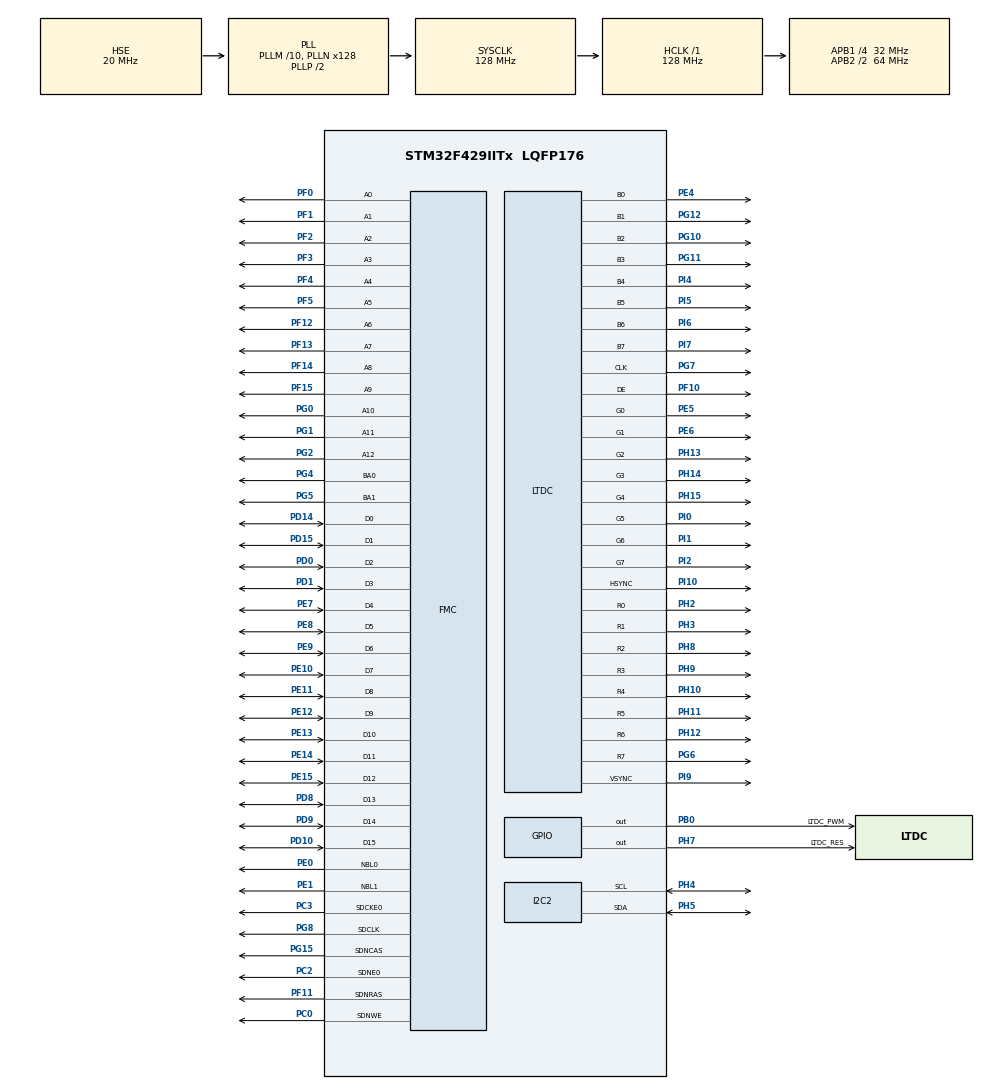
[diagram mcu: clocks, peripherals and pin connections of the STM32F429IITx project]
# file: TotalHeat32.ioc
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FMC.CASLatency1=FMC_SDRAM_CAS_LATENCY_2
FMC.ColumnBitsNumber1=FMC_SDRAM_COLUMN_BITS_NUM_9
FMC.ExitSelfRefreshDelay1=1
FMC.LoadToActiveDelay1=1
FMC.RCDDelay1=1
FMC.RPDelay1=1
FMC.RowCycleDelay1=4
FMC.SDClockPeriod1=FMC_SDRAM_CLOCK_PERIOD_2
FMC.SelfRefreshTime1=1
FMC.WriteRecoveryTime1=2
LTDC.ActiveW=800
LTDC.Green=0
LTDC.HBP=88
LTDC.HFP=40
LTDC.HSync=48
LTDC.Layers=0
LTDC.VBP=32
LTDC.VFP=13
LTDC.VSync=3
Mcu.Family=STM32F4
Mcu.Name=STM32F429IITx
Mcu.Package=LQFP176
NVIC.PriorityGroup=NVIC_PRIORITYGROUP_4
NVIC.TIM1_UP_TIM10_IRQn=true\:15\:0\:false\:false\:true\:false\:true
NVIC.TimeBase=TIM1_UP_TIM10_IRQn
NVIC.TimeBaseIP=TIM1
PB0.GPIO_Label=LTDC_PWM
PB0.GPIO_PuPd=GPIO_NOPULL
PB0.Signal=GPIO_Output
PC0.Signal=FMC_SDNWE
PC2.Mode=SdramChipSelect1_1
PC2.Signal=FMC_SDNE0
PC3.Mode=SdramChipSelect1_1
PC3.Signal=FMC_SDCKE0
PD0.Signal=FMC_D2_DA2
PD1.Signal=FMC_D3_DA3
PD10.Signal=FMC_D15_DA15
PD14.Signal=FMC_D0_DA0
PD15.Signal=FMC_D1_DA1
PD8.Signal=FMC_D13_DA13
PD9.Signal=FMC_D14_DA14
PE0.Signal=FMC_NBL0
PE1.Signal=FMC_NBL1
PE10.Signal=FMC_D7_DA7
PE11.Signal=FMC_D8_DA8
PE12.Signal=FMC_D9_DA9
PE13.Signal=FMC_D10_DA10
PE14.Signal=FMC_D11_DA11
PE15.Signal=FMC_D12_DA12
PE4.Mode=RGB888
PE4.Signal=LTDC_B0
PE5.Mode=RGB888
PE5.Signal=LTDC_G0
PE6.Mode=RGB888
PE6.Signal=LTDC_G1
PE7.Signal=FMC_D4_DA4
PE8.Signal=FMC_D5_DA5
PE9.Signal=FMC_D6_DA6
PF0.Signal=FMC_A0
PF1.Signal=FMC_A1
PF10.Mode=RGB888
PF10.Signal=LTDC_DE
PF11.Signal=FMC_SDNRAS
PF12.Signal=FMC_A6
PF13.Signal=FMC_A7
PF14.Signal=FMC_A8
PF15.Signal=FMC_A9
PF2.Signal=FMC_A2
PF3.Signal=FMC_A3
PF4.Signal=FMC_A4
PF5.Signal=FMC_A5
PG0.Signal=FMC_A10
PG1.Signal=FMC_A11
PG10.Mode=RGB888
PG10.Signal=LTDC_B2
PG11.Mode=RGB888
PG11.Signal=LTDC_B3
PG12.Mode=RGB888
PG12.Signal=LTDC_B1
PG15.Signal=FMC_SDNCAS
PG2.Signal=FMC_A12
PG4.Signal=FMC_A14_BA0
PG5.Signal=FMC_A15_BA1
PG6.Mode=RGB888
PG6.Signal=LTDC_R7
PG7.Mode=RGB888
PG7.Signal=LTDC_CLK
PG8.Signal=FMC_SDCLK
PH0/OSC_IN.Mode=HSE-External-Oscillator
PH0/OSC_IN.Signal=RCC_OSC_IN
PH1/OSC_OUT.Mode=HSE-External-Oscillator
PH1/OSC_OUT.Signal=RCC_OSC_OUT
PH10.Mode=RGB888
PH10.Signal=LTDC_R4
PH11.Mode=RGB888
PH11.Signal=LTDC_R5
PH12.Mode=RGB888
PH12.Signal=LTDC_R6
PH13.Mode=RGB888
PH13.Signal=LTDC_G2
PH14.Mode=RGB888
PH14.Signal=LTDC_G3
PH15.Mode=RGB888
PH15.Signal=LTDC_G4
PH2.Mode=RGB888
PH2.Signal=LTDC_R0
PH3.Mode=RGB888
PH3.Signal=LTDC_R1
PH4.GPIO_Pu=GPIO_PULLUP
PH4.Mode=I2C
PH4.Signal=I2C2_SCL
PH5.GPIO_Pu=GPIO_PULLUP
PH5.Mode=I2C
PH5.Signal=I2C2_SDA
PH7.GPIO_Label=LTDC_RES
PH7.GPIO_PuPd=GPIO_NOPULL
PH7.Signal=GPIO_Output
PH8.Mode=RGB888
PH8.Signal=LTDC_R2
PH9.Mode=RGB888
PH9.Signal=LTDC_R3
PI0.Mode=RGB888
PI0.Signal=LTDC_G5
PI1.Mode=RGB888
PI1.Signal=LTDC_G6
PI10.Mode=RGB888
PI10.Signal=LTDC_HSYNC
PI2.Mode=RGB888
PI2.Signal=LTDC_G7
PI4.Mode=RGB888
PI4.Signal=LTDC_B4
PI5.Mode=RGB888
PI5.Signal=LTDC_B5
PI6.Mode=RGB888
PI6.Signal=LTDC_B6
PI7.Mode=RGB888
PI7.Signal=LTDC_B7
PI9.Mode=RGB888
PI9.Signal=LTDC_VSYNC
ProjectManager.HeapSize=0x200
ProjectManager.StackSize=0x400
ProjectManager.TargetToolchain=STM32CubeIDE
RCC.48MHZClocksFreq_Value=64000000
RCC.AHBFreq_Value=128000000
RCC.APB1CLKDivider=RCC_HCLK_DIV4
RCC.APB1Freq_Value=32000000
RCC.APB1TimFreq_Value=64000000
RCC.APB2CLKDivider=RCC_HCLK_DIV2
RCC.APB2Freq_Value=64000000
RCC.APB2TimFreq_Value=128000000
RCC.CortexFreq_Value=128000000
RCC.HCLKFreq_Value=128000000
RCC.HSE_VALUE=20000000
RCC.HSI_VALUE=16000000
RCC.LSE_VALUE=32768
RCC.PLLM=10
RCC.PLLN=128
RCC.PLLSAIN=50
RCC.PLLSourceVirtual=RCC_PLLSOURCE_HSE
RCC.SYSCLKFreq_VALUE=128000000
RCC.SYSCLKSource=RCC_SYSCLKSOURCE_PLLCLK
RCC.VCOOutputFreq_Value=256000000
SH.FMC_A0.0=FMC_A0,13b-sda1
SH.FMC_A1.0=FMC_A1,13b-sda1
SH.FMC_A10.0=FMC_A10,13b-sda1
SH.FMC_A11.0=FMC_A11,13b-sda1
SH.FMC_A12.0=FMC_A12,13b-sda1
SH.FMC_A14_BA0.0=FMC_BA0,FourSdramBanks1
SH.FMC_A15_BA1.0=FMC_BA1,FourSdramBanks1
SH.FMC_A2.0=FMC_A2,13b-sda1
SH.FMC_A3.0=FMC_A3,13b-sda1
SH.FMC_A4.0=FMC_A4,13b-sda1
SH.FMC_A5.0=FMC_A5,13b-sda1
SH.FMC_A6.0=FMC_A6,13b-sda1
SH.FMC_A7.0=FMC_A7,13b-sda1
SH.FMC_A8.0=FMC_A8,13b-sda1
SH.FMC_A9.0=FMC_A9,13b-sda1
SH.FMC_D0_DA0.0=FMC_D0,sd-16b-d1
SH.FMC_D10_DA10.0=FMC_D10,sd-16b-d1
SH.FMC_D11_DA11.0=FMC_D11,sd-16b-d1
SH.FMC_D12_DA12.0=FMC_D12,sd-16b-d1
SH.FMC_D13_DA13.0=FMC_D13,sd-16b-d1
SH.FMC_D14_DA14.0=FMC_D14,sd-16b-d1
SH.FMC_D15_DA15.0=FMC_D15,sd-16b-d1
SH.FMC_D1_DA1.0=FMC_D1,sd-16b-d1
SH.FMC_D2_DA2.0=FMC_D2,sd-16b-d1
SH.FMC_D3_DA3.0=FMC_D3,sd-16b-d1
SH.FMC_D4_DA4.0=FMC_D4,sd-16b-d1
SH.FMC_D5_DA5.0=FMC_D5,sd-16b-d1
SH.FMC_D6_DA6.0=FMC_D6,sd-16b-d1
SH.FMC_D7_DA7.0=FMC_D7,sd-16b-d1
SH.FMC_D8_DA8.0=FMC_D8,sd-16b-d1
SH.FMC_D9_DA9.0=FMC_D9,sd-16b-d1
SH.FMC_NBL0.0=FMC_NBL0,Sd2ByteEnable1
SH.FMC_NBL1.0=FMC_NBL1,Sd2ByteEnable1
SH.FMC_SDCLK.0=FMC_SDCLK,13b-sda1
SH.FMC_SDNCAS.0=FMC_SDNCAS,13b-sda1
SH.FMC_SDNRAS.0=FMC_SDNRAS,13b-sda1
SH.FMC_SDNWE.0=FMC_SDNWE,13b-sda1
VP_SYS_VS_tim1.Mode=TIM1
board=custom

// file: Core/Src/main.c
/* USER CODE BEGIN Header */
/**
  ******************************************************************************
  * @file           : main.c
  * @brief          : Main program body
  ******************************************************************************
  * @attention
  *
  * Copyright (c) 2022 STMicroelectronics.
  * All rights reserved.
  *
  * This software is licensed under terms that can be found in the LICENSE file
  * in the root directory of this software component.
  * If no LICENSE file comes with this software, it is provided AS-IS.
  *
  ******************************************************************************
  */
/* USER CODE END Header */
#include "main.h"

/* USER CODE BEGIN Includes */
#include "W9812G6.h"
/* USER CODE END Includes */

I2C_HandleTypeDef hi2c2;

LTDC_HandleTypeDef hltdc;

SDRAM_HandleTypeDef hsdram1;

void SystemClock_Config(void);
static void MX_GPIO_Init(void);
static void MX_LTDC_Init(void);
static void MX_FMC_Init(void);
static void MX_I2C2_Init(void);

/* USER CODE BEGIN 0 */
void init_layers(void)
{
	w9812g6_init(&hsdram1);
	for(uint8_t i=0; i<MAX_LAYER;i++)
	{
		HAL_LTDC_SetAddress(&hltdc,LCD_FRAME_BUFFER(i), i);
	}
	HAL_GPIO_WritePin(LTDC_PWM_GPIO_Port, LTDC_PWM_Pin, GPIO_PIN_SET);
	test_draw_all();
}
/* USER CODE END 0 */

int main(void)
{

  /* MCU Configuration--------------------------------------------------------*/

  /* Reset of all peripherals, Initializes the Flash interface and the Systick. */
  HAL_Init();

  /* Configure the system clock */
  SystemClock_Config();

  /* Initialize all configured peripherals */
  MX_GPIO_Init();
  MX_LTDC_Init();
  MX_FMC_Init();
  MX_I2C2_Init();

  /* Infinite loop */
  while (1)
  {

    /* USER CODE BEGIN 3 */
	handle_ms_tick(HAL_GetTick());
  }
  /* USER CODE END 3 */
}

void SystemClock_Config(void)
{
  RCC_OscInitTypeDef RCC_OscInitStruct = {0};
  RCC_ClkInitTypeDef RCC_ClkInitStruct = {0};

  /** Configure the main internal regulator output voltage
  */
  __HAL_RCC_PWR_CLK_ENABLE();
  __HAL_PWR_VOLTAGESCALING_CONFIG(PWR_REGULATOR_VOLTAGE_SCALE2);
  /** Initializes the RCC Oscillators according to the specified parameters
  * in the RCC_OscInitTypeDef structure.
  */
  RCC_OscInitStruct.OscillatorType = RCC_OSCILLATORTYPE_HSE;
  RCC_OscInitStruct.HSEState = RCC_HSE_ON;
  RCC_OscInitStruct.PLL.PLLState = RCC_PLL_ON;
  RCC_OscInitStruct.PLL.PLLSource = RCC_PLLSOURCE_HSE;
  RCC_OscInitStruct.PLL.PLLM = 10;
  RCC_OscInitStruct.PLL.PLLN = 128;
  RCC_OscInitStruct.PLL.PLLP = RCC_PLLP_DIV2;
  RCC_OscInitStruct.PLL.PLLQ = 4;
  if (HAL_RCC_OscConfig(&RCC_OscInitStruct) != HAL_OK)
  {
    Error_Handler();
  }
  /** Initializes the CPU, AHB and APB buses clocks
  */
  RCC_ClkInitStruct.ClockType = RCC_CLOCKTYPE_HCLK|RCC_CLOCKTYPE_SYSCLK
                              |RCC_CLOCKTYPE_PCLK1|RCC_CLOCKTYPE_PCLK2;
  RCC_ClkInitStruct.SYSCLKSource = RCC_SYSCLKSOURCE_PLLCLK;
  RCC_ClkInitStruct.AHBCLKDivider = RCC_SYSCLK_DIV1;
  RCC_ClkInitStruct.APB1CLKDivider = RCC_HCLK_DIV4;
  RCC_ClkInitStruct.APB2CLKDivider = RCC_HCLK_DIV2;

  if (HAL_RCC_ClockConfig(&RCC_ClkInitStruct, FLASH_LATENCY_4) != HAL_OK)
  {
    Error_Handler();
  }
}

static void MX_I2C2_Init(void)
{

  hi2c2.Instance = I2C2;
  hi2c2.Init.ClockSpeed = 100000;
  hi2c2.Init.DutyCycle = I2C_DUTYCYCLE_2;
  hi2c2.Init.OwnAddress1 = 0;
  hi2c2.Init.AddressingMode = I2C_ADDRESSINGMODE_7BIT;
  hi2c2.Init.DualAddressMode = I2C_DUALADDRESS_DISABLE;
  hi2c2.Init.OwnAddress2 = 0;
  hi2c2.Init.GeneralCallMode = I2C_GENERALCALL_DISABLE;
  hi2c2.Init.NoStretchMode = I2C_NOSTRETCH_DISABLE;
  if (HAL_I2C_Init(&hi2c2) != HAL_OK)
  {
    Error_Handler();
  }
  /** Configure Analogue filter
  */
  if (HAL_I2CEx_ConfigAnalogFilter(&hi2c2, I2C_ANALOGFILTER_ENABLE) != HAL_OK)
  {
    Error_Handler();
  }
  /** Configure Digital filter
  */
  if (HAL_I2CEx_ConfigDigitalFilter(&hi2c2, 0) != HAL_OK)
  {
    Error_Handler();
  }

}

static void MX_LTDC_Init(void)
{

  LTDC_LayerCfgTypeDef pLayerCfg = {0};

  hltdc.Instance = LTDC;
  hltdc.Init.HSPolarity = LTDC_HSPOLARITY_AL;
  hltdc.Init.VSPolarity = LTDC_VSPOLARITY_AL;
  hltdc.Init.DEPolarity = LTDC_DEPOLARITY_AL;
  hltdc.Init.PCPolarity = LTDC_PCPOLARITY_IPC;
  hltdc.Init.HorizontalSync = 47;
  hltdc.Init.VerticalSync = 2;
  hltdc.Init.AccumulatedHBP = 135;
  hltdc.Init.AccumulatedVBP = 34;
  hltdc.Init.AccumulatedActiveW = 935;
  hltdc.Init.AccumulatedActiveH = 514;
  hltdc.Init.TotalWidth = 975;
  hltdc.Init.TotalHeigh = 527;
  hltdc.Init.Backcolor.Blue = 0;
  hltdc.Init.Backcolor.Green = 0;
  hltdc.Init.Backcolor.Red = 0;
  if (HAL_LTDC_Init(&hltdc) != HAL_OK)
  {
    Error_Handler();
  }
  pLayerCfg.WindowX0 = 0;
  pLayerCfg.WindowX1 = 0;
  pLayerCfg.WindowY0 = 0;
  pLayerCfg.WindowY1 = 0;
  pLayerCfg.PixelFormat = LTDC_PIXEL_FORMAT_ARGB8888;
  pLayerCfg.Alpha = 0;
  pLayerCfg.Alpha0 = 0;
  pLayerCfg.BlendingFactor1 = LTDC_BLENDING_FACTOR1_CA;
  pLayerCfg.BlendingFactor2 = LTDC_BLENDING_FACTOR2_CA;
  pLayerCfg.FBStartAdress = 0;
  pLayerCfg.ImageWidth = 0;
  pLayerCfg.ImageHeight = 0;
  pLayerCfg.Backcolor.Blue = 0;
  pLayerCfg.Backcolor.Green = 0;
  pLayerCfg.Backcolor.Red = 0;
  if (HAL_LTDC_ConfigLayer(&hltdc, &pLayerCfg, 0) != HAL_OK)
  {
    Error_Handler();
  }
  /* USER CODE BEGIN LTDC_Init 2 */
  hltdc.Instance = LTDC;
  hltdc.Init.HSPolarity = LTDC_HSPOLARITY_AL;
  hltdc.Init.VSPolarity = LTDC_VSPOLARITY_AL;
  hltdc.Init.DEPolarity = LTDC_DEPOLARITY_AL;
  hltdc.Init.PCPolarity = LTDC_PCPOLARITY_IPC;

  const int Horizontal_Synchronization_Width      = 48;//Horizontal Synchronization Width must be between 1 pixels and 4.095 Kpixels.
  const int Horizontal_Back_Porch	                =	88;// 	Horizontal Back Porch must be between 0 pixels and 4.095 Kpixels.
  const int Horizontal_Front_Porch                = 40;//    Horizontal Front Porch must be between 0 pixels and 4.095 Kpixels.
  const int Vertical_Synchronization_Height       = 3;//		  Vertical Synchronization Height must be between 1 lines and 2.047 Klines.
  const int Vertical_Back_Porch                   = 32;// 		Vertical Back Porch must be between 0 lines and 2.047 Klines.
  const int Vertical_Front_Porch                  = 13;//		Vertical Front Porch must be between 0 lines and 2.047 Klines.

  hltdc.Init.HorizontalSync = Horizontal_Synchronization_Width-1;//127;      //This register value is equal to (Horizontal Synchronization Width - 1)
  hltdc.Init.VerticalSync = Vertical_Synchronization_Height-1;          //This register value is equal to (Vertical Synchronization Width - 1)
  hltdc.Init.AccumulatedHBP = Horizontal_Synchronization_Width+Horizontal_Back_Porch-1;      //This register value is equal to the (Horizontal Synchronization Width + Horizontal Back Porch - 1)
  hltdc.Init.AccumulatedVBP = Vertical_Synchronization_Height+Vertical_Back_Porch-1;       //This register value is equal to the (Vertical Synchronization Width + Vertical Back Porch - 1)
  hltdc.Init.AccumulatedActiveW = MX_DISPLAY_WIDTH+Horizontal_Synchronization_Width+Horizontal_Back_Porch-1; //This register value is equal to (Horizontal Synchronization Width + Horizontal Back Porch + Active Width - 1)
  hltdc.Init.AccumulatedActiveH = MX_DISPLAY_HEIGHT+Vertical_Synchronization_Height+Vertical_Back_Porch-1;  //This register value is equal to the (Vertical Synchronization Width + Vertical Back Porch + Active Height - 1)
  hltdc.Init.TotalWidth = MX_DISPLAY_WIDTH+Horizontal_Synchronization_Width+Horizontal_Back_Porch+Horizontal_Front_Porch-1;          //This register value is equal to (Horizontal Synchronization Width + Horizontal Back Porch + Active Width + Horizontal Front Porch - 1)
  hltdc.Init.TotalHeigh = MX_DISPLAY_HEIGHT+Vertical_Synchronization_Height+Vertical_Back_Porch+Vertical_Front_Porch-1;          //This register value is equal to the (Vertical Synchronization Width + Vertical Back Porch + Active Height + Vertical Front Porch - 1)
  hltdc.Init.Backcolor.Blue = 0;
  hltdc.Init.Backcolor.Green = 0;
  hltdc.Init.Backcolor.Red = 0;
  if (HAL_LTDC_Init(&hltdc) != HAL_OK)
  {
    Error_Handler();
  }
  for(int n=0;n<MAX_LAYER;n++){
	  pLayerCfg.WindowX0 = 0;
	  pLayerCfg.WindowX1 = n==0?MX_DISPLAY_WIDTH:0;
	  pLayerCfg.WindowY0 = 0;
	  pLayerCfg.WindowY1 = n==0?MX_DISPLAY_HEIGHT:0;
	  pLayerCfg.PixelFormat = LTDC_PIXEL_FORMAT_ARGB8888;
	  pLayerCfg.Alpha = 255;
	  pLayerCfg.Alpha0 = 0;
	  pLayerCfg.BlendingFactor1 = LTDC_BLENDING_FACTOR1_PAxCA;
	  pLayerCfg.BlendingFactor2 = LTDC_BLENDING_FACTOR2_PAxCA;
	  pLayerCfg.FBStartAdress = LCD_FRAME_BUFFER(n);
	  pLayerCfg.ImageWidth = MX_DISPLAY_WIDTH;
	  pLayerCfg.ImageHeight = MX_DISPLAY_HEIGHT;
	  pLayerCfg.Backcolor.Blue = 0;
	  pLayerCfg.Backcolor.Green = 0;
	  pLayerCfg.Backcolor.Red = 0;
	  if (HAL_LTDC_ConfigLayer(&hltdc, &pLayerCfg, n) != HAL_OK)
	  {
		Error_Handler();
	  }
  }
  /* USER CODE END LTDC_Init 2 */

}

/* FMC initialization function */
static void MX_FMC_Init(void)
{

  FMC_SDRAM_TimingTypeDef SdramTiming = {0};

  /** Perform the SDRAM1 memory initialization sequence
  */
  hsdram1.Instance = FMC_SDRAM_DEVICE;
  /* hsdram1.Init */
  hsdram1.Init.SDBank = FMC_SDRAM_BANK1;
  hsdram1.Init.ColumnBitsNumber = FMC_SDRAM_COLUMN_BITS_NUM_9;
  hsdram1.Init.RowBitsNumber = FMC_SDRAM_ROW_BITS_NUM_13;
  hsdram1.Init.MemoryDataWidth = FMC_SDRAM_MEM_BUS_WIDTH_16;
  hsdram1.Init.InternalBankNumber = FMC_SDRAM_INTERN_BANKS_NUM_4;
  hsdram1.Init.CASLatency = FMC_SDRAM_CAS_LATENCY_2;
  hsdram1.Init.WriteProtection = FMC_SDRAM_WRITE_PROTECTION_DISABLE;
  hsdram1.Init.SDClockPeriod = FMC_SDRAM_CLOCK_PERIOD_2;
  hsdram1.Init.ReadBurst = FMC_SDRAM_RBURST_DISABLE;
  hsdram1.Init.ReadPipeDelay = FMC_SDRAM_RPIPE_DELAY_0;
  /* SdramTiming */
  SdramTiming.LoadToActiveDelay = 1;
  SdramTiming.ExitSelfRefreshDelay = 1;
  SdramTiming.SelfRefreshTime = 1;
  SdramTiming.RowCycleDelay = 4;
  SdramTiming.WriteRecoveryTime = 2;
  SdramTiming.RPDelay = 1;
  SdramTiming.RCDDelay = 1;

  if (HAL_SDRAM_Init(&hsdram1, &SdramTiming) != HAL_OK)
  {
    Error_Handler( );
  }

}

static void MX_GPIO_Init(void)
{
  GPIO_InitTypeDef GPIO_InitStruct = {0};

  /* GPIO Ports Clock Enable */
  __HAL_RCC_GPIOE_CLK_ENABLE();
  __HAL_RCC_GPIOI_CLK_ENABLE();
  __HAL_RCC_GPIOF_CLK_ENABLE();
  __HAL_RCC_GPIOH_CLK_ENABLE();
  __HAL_RCC_GPIOC_CLK_ENABLE();
  __HAL_RCC_GPIOB_CLK_ENABLE();
  __HAL_RCC_GPIOG_CLK_ENABLE();
  __HAL_RCC_GPIOD_CLK_ENABLE();

  /*Configure GPIO pin Output Level */
  HAL_GPIO_WritePin(LTDC_PWM_GPIO_Port, LTDC_PWM_Pin, GPIO_PIN_RESET);

  /*Configure GPIO pin Output Level */
  HAL_GPIO_WritePin(LTDC_RES_GPIO_Port, LTDC_RES_Pin, GPIO_PIN_RESET);

  /*Configure GPIO pin : LTDC_PWM_Pin */
  GPIO_InitStruct.Pin = LTDC_PWM_Pin;
  GPIO_InitStruct.Mode = GPIO_MODE_OUTPUT_PP;
  GPIO_InitStruct.Pull = GPIO_NOPULL;
  GPIO_InitStruct.Speed = GPIO_SPEED_FREQ_LOW;
  HAL_GPIO_Init(LTDC_PWM_GPIO_Port, &GPIO_InitStruct);

  /*Configure GPIO pin : LTDC_RES_Pin */
  GPIO_InitStruct.Pin = LTDC_RES_Pin;
  GPIO_InitStruct.Mode = GPIO_MODE_OUTPUT_PP;
  GPIO_InitStruct.Pull = GPIO_NOPULL;
  GPIO_InitStruct.Speed = GPIO_SPEED_FREQ_LOW;
  HAL_GPIO_Init(LTDC_RES_GPIO_Port, &GPIO_InitStruct);

}

/* USER CODE BEGIN 4 */
void delay_us(uint32_t delay)
{
	uint32_t i=0;
	//byte j=0;
	for (i=0;i<(delay*10);i++)
	{
		asm("NOP");
	}
}
/* USER CODE END 4 */

void HAL_TIM_PeriodElapsedCallback(TIM_HandleTypeDef *htim)
{
  if (htim->Instance == TIM1) {
    HAL_IncTick();
  }
}

void Error_Handler(void)
{
  __disable_irq();
  while (1)
  {
  }
}
